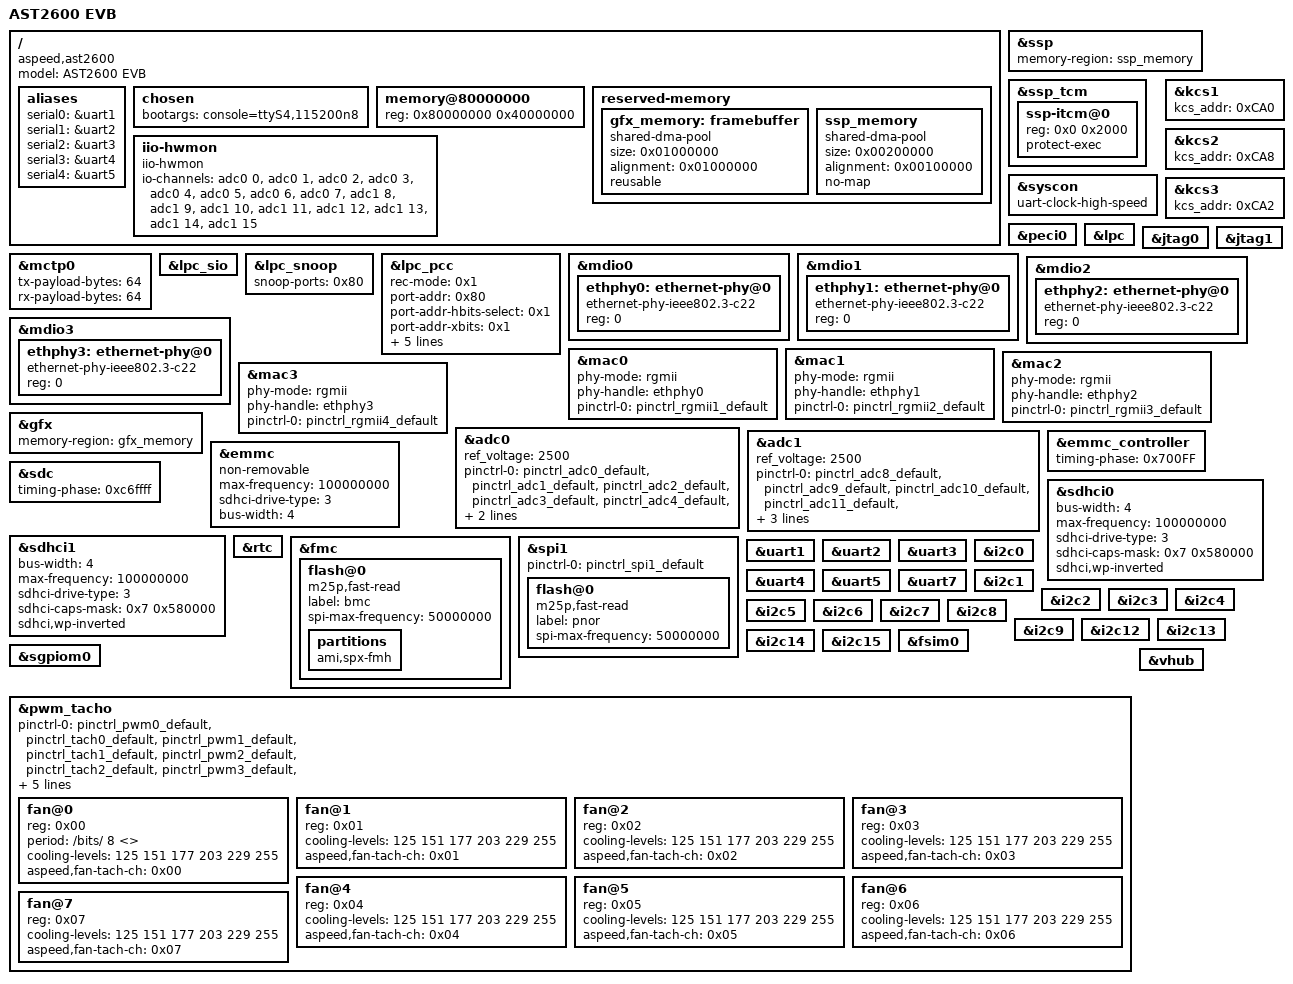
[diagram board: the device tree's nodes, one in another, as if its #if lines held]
// SPDX-License-Identifier: GPL-2.0-or-later
// Copyright 2019 IBM Corp.

/dts-v1/;

#include "projdef.h"
#include "aspeed-g6.dtsi"
#include <dt-bindings/gpio/aspeed-gpio.h>
#include <dt-bindings/i2c/i2c.h>

/ {
	model = "AST2600 EVB";
	compatible = "aspeed,ast2600";

	aliases {
		serial0 = &uart1;
		serial1 = &uart2;
		serial2 = &uart3;
		serial3 = &uart4;
		serial4 = &uart5;
	};

	chosen {
		bootargs = "console=ttyS4,115200n8";
	};

	memory@80000000 {
		device_type = "memory";
		reg = <0x80000000 0x40000000>;
	};
	
    reserved-memory {
		#address-cells = <1>;
		#size-cells = <1>;
		ranges;

		gfx_memory: framebuffer {
			size = <0x01000000>;
			alignment = <0x01000000>;
			compatible = "shared-dma-pool";
			reusable;
		};
            
		ssp_memory: ssp_memory {
			size = <0x00200000>;
			alignment = <0x00100000>;
			compatible = "shared-dma-pool";
			no-map;
		};          
     };



    iio-hwmon {
        compatible = "iio-hwmon";
        io-channels = <&adc0 0>, <&adc0 1>, <&adc0 2>, <&adc0 3>,
                        <&adc0 4>, <&adc0 5>, <&adc0 6>, <&adc0 7>,
                        <&adc1 8>, <&adc1 9>, <&adc1 10>, <&adc1 11>,
                        <&adc1 12>, <&adc1 13>, <&adc1 14>, <&adc1 15>;
    };

};
#if defined(CONFIG_SPX_FEATURE_ENABLE_SSP)
&ssp {
	memory-region = <&ssp_memory>;
};

&ssp_tcm {
	#address-cells = <1>;
	#size-cells = <1>;
	ranges = <0 0x1a000000 0x2000>;
	ssp-itcm@0 {
		reg = <0x0 0x2000>;
		protect-exec;
	};
};
#endif

&syscon {
        uart-clock-high-speed;
        status = "okay";
};

&kcs1 {
        kcs_addr = <0xCA0>;
        status = "okay";
};

&kcs2 {
        kcs_addr = <0xCA8>;
        status = "okay";
};

&kcs3 {
        kcs_addr = <0xCA2>;
        status = "okay";
};

&peci0 {
    status = "okay";
};

&lpc {
    status = "okay";
};

&jtag0 {
        status = "okay";
};

&jtag1 {
        status = "okay";
};

&mctp0 {
    tx-payload-bytes= <64>;
    rx-payload-bytes= <64>;
    status = "okay";
};
&lpc_sio {
        status = "okay";
};

&lpc_snoop {
        snoop-ports = <0x80>;
        status = "okay";
};

&lpc_pcc { 
	rec-mode = <0x1>; 
	port-addr = <0x80>; 
	port-addr-hbits-select = <0x1>; 
	port-addr-xbits = <0x1>; 
	pattern-a-en; 
	pattern-a = <0x41424344>; 
	pattern-a-len = <0x4>; 
	pattern-a-write = <0x1>; 
	pattern-a-port = <0x80>; 
	status = "okay"; 
};

&mdio0 {
        status = "okay";

        ethphy0: ethernet-phy@0 {
                compatible = "ethernet-phy-ieee802.3-c22";
                reg = <0>;
        };
};

&mdio1 {
	status = "okay";

	ethphy1: ethernet-phy@0 {
		compatible = "ethernet-phy-ieee802.3-c22";
		reg = <0>;
	};
};

&mdio2 {
	status = "okay";

	ethphy2: ethernet-phy@0 {
		compatible = "ethernet-phy-ieee802.3-c22";
		reg = <0>;
	};
};

&mdio3 {
	status = "okay";

	ethphy3: ethernet-phy@0 {
		compatible = "ethernet-phy-ieee802.3-c22";
		reg = <0>;
	};
};

&mac0 {
        status = "okay";

        phy-mode = "rgmii";
        phy-handle = <&ethphy0>;

        pinctrl-names = "default";
        pinctrl-0 = <&pinctrl_rgmii1_default>;
};

&mac1 {
	status = "okay";

	phy-mode = "rgmii";
	phy-handle = <&ethphy1>;

	pinctrl-names = "default";
	pinctrl-0 = <&pinctrl_rgmii2_default>;
};

&mac2 {
	status = "okay";

	phy-mode = "rgmii";
	phy-handle = <&ethphy2>;

	pinctrl-names = "default";
	pinctrl-0 = <&pinctrl_rgmii3_default>;
};

&mac3 {
	status = "okay";

	phy-mode = "rgmii";
	phy-handle = <&ethphy3>;

	pinctrl-names = "default";
	pinctrl-0 = <&pinctrl_rgmii4_default>;
};

&adc0 {
	ref_voltage = <2500>;
	status = "okay";

	pinctrl-names = "default";
	pinctrl-0 = <&pinctrl_adc0_default &pinctrl_adc1_default
		&pinctrl_adc2_default &pinctrl_adc3_default
		&pinctrl_adc4_default &pinctrl_adc5_default
		&pinctrl_adc6_default &pinctrl_adc7_default>;
};

&adc1 {
	ref_voltage = <2500>;
	status = "okay";

	pinctrl-names = "default";
	pinctrl-0 = <&pinctrl_adc8_default &pinctrl_adc9_default
		&pinctrl_adc10_default &pinctrl_adc11_default
		&pinctrl_adc12_default &pinctrl_adc13_default
		&pinctrl_adc14_default &pinctrl_adc15_default>;
};

&gfx {
        status = "okay";
        memory-region = <&gfx_memory>;
};

&emmc_controller {
	status = "okay";
	timing-phase = <0x700FF>;
};

&emmc {
    status = "okay";
    non-removable;
    max-frequency = <100000000>;
    sdhci-drive-type = /bits/ 8 <3>;
#if 1
    bus-width = <4>;
#else
    bus-width = <8>;
    pinctrl-0 = <&pinctrl_emmc_default
            &pinctrl_emmcg8_default>;
#endif

};

&sdc {
	status = "okay";
	timing-phase = <0xc6ffff>;
};

&sdhci0 {
    status = "okay";
    bus-width = <4>;
    max-frequency = <100000000>;
    sdhci-drive-type = /bits/ 8 <3>;
    /* SDR104/DDR50/SDR50 bits in CAPA2 is not supported */
    sdhci-caps-mask = <0x7 0x580000>;
    sdhci,wp-inverted;
};

#if !defined(CONFIG_SPX_FEATURE_ENABLE_SSP)
&sdhci1 {
    status = "okay";
    bus-width = <4>;
    max-frequency = <100000000>;
    sdhci-drive-type = /bits/ 8 <3>;
    sdhci-caps-mask = <0x7 0x580000>;
    sdhci,wp-inverted;
};
#endif

&rtc {
	status = "okay";
};

&fmc {
	status = "okay";
	flash@0 {
		status = "okay";
		m25p,fast-read;
		label = "bmc";
		spi-max-frequency = <50000000>;
        partitions {
            compatible = "ami,spx-fmh";
        };
	};
};

&spi1 {
	status = "okay";
	pinctrl-names = "default";
	pinctrl-0 = <&pinctrl_spi1_default>;

	flash@0 {
		status = "okay";
		m25p,fast-read;
		label = "pnor";
		spi-max-frequency = <50000000>;
	};
};

&uart1 {
	status = "okay";
};

&uart2 {
	status = "okay";
};

&uart3 {
	status = "okay";
};

&uart4 {
	status = "okay";
};

&uart5 {
	status = "okay";
};

#if defined(CONFIG_SPX_FEATURE_ENABLE_SSP)
&uart7 {
	status = "okay";
};
#endif

&i2c0 {
	status = "okay";
};

&i2c1 {
	status = "okay";
};

&i2c2 {
	status = "okay";
};

&i2c3 {
	status = "okay";
};

&i2c4 {
	status = "okay";
};

&i2c5 {
	status = "okay";
};

&i2c6 {
	status = "okay";
};

&i2c7 {
	status = "okay";
};

&i2c8 {
	status = "okay";
};

&i2c9 {
	status = "okay";
};

&i2c12 {
	status = "okay";
};

&i2c13 {
	status = "okay";
};

&i2c14 {
	status = "okay";
};

&i2c15 {
	status = "okay";
};

&fsim0 {
	status = "okay";
};
&sgpiom0 {
        status = "okay";
};

&pwm_tacho {
        status = "okay";
        pinctrl-names = "default";
        pinctrl-0 = <&pinctrl_pwm0_default &pinctrl_tach0_default
                        &pinctrl_pwm1_default &pinctrl_tach1_default
                        &pinctrl_pwm2_default &pinctrl_tach2_default
                        &pinctrl_pwm3_default &pinctrl_tach3_default
                        &pinctrl_pwm4_default &pinctrl_tach4_default
                        &pinctrl_pwm5_default &pinctrl_tach5_default
                        &pinctrl_pwm6_default &pinctrl_tach6_default
                        &pinctrl_pwm7_default &pinctrl_tach7_default>;

        fan@0 {
                reg = <0x00>;
                period = /bits/ 8 <>;
                cooling-levels = /bits/ 8 <125 151 177 203 229 255>;
                aspeed,fan-tach-ch = /bits/ 8 <0x00>;
        };

        fan@1 {
                reg = <0x01>;
                cooling-levels = /bits/ 8 <125 151 177 203 229 255>;
                aspeed,fan-tach-ch = /bits/ 8 <0x01>;
        };

        fan@2 {
                reg = <0x02>;
                cooling-levels = /bits/ 8 <125 151 177 203 229 255>;
                aspeed,fan-tach-ch = /bits/ 8 <0x02>;
        };

        fan@3 {
                reg = <0x03>;
                cooling-levels = /bits/ 8 <125 151 177 203 229 255>;
                aspeed,fan-tach-ch = /bits/ 8 <0x03>;
        };

        fan@4 {
                reg = <0x04>;
                cooling-levels = /bits/ 8 <125 151 177 203 229 255>;
                aspeed,fan-tach-ch = /bits/ 8 <0x04>;
        };

        fan@5 {
                reg = <0x05>;
                cooling-levels = /bits/ 8 <125 151 177 203 229 255>;
                aspeed,fan-tach-ch = /bits/ 8 <0x05>;
        };

        fan@6 {
                reg = <0x06>;
                cooling-levels = /bits/ 8 <125 151 177 203 229 255>;
                aspeed,fan-tach-ch = /bits/ 8 <0x06>;
        };

        fan@7 {
                reg = <0x07>;
                cooling-levels = /bits/ 8 <125 151 177 203 229 255>;
                aspeed,fan-tach-ch = /bits/ 8 <0x07>;
        };

   
};

&vhub {
        status = "okay";
};

#include "legacy.dtsi" /* For Legacy AMI Drivers */

